# file10 register map
Vendor: Test Ltd.; Series: TestSeries; File version: 1.0
Test svd file for enumeratedValues derivedFrom
Registers are 32-bit, read-write, reset 0x0 unless marked. A register's access mark holds for its fields unless they carry their own. Offsets are from the block's base; lines under a group give offsets from that group; [hi:lo] are bit positions; {n}, {i} and the like mark numbered series; 'fields as' and 'values as' point back to an identical list; <NAME> marks a mode.

## Memory map
0x40000000 TestPeripheral

## TestPeripheral
Base 0x40000000
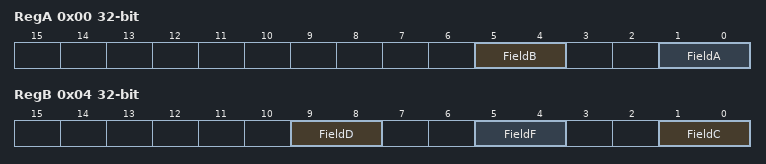
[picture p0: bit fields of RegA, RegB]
0x00 RegA — Register with the origin enumeratedValues sections
  [5:4] FieldB — Derives its enumeratedValues by a bare, unqualified name
    0=Disable device; 1=Enable device
  [1:0] FieldA — Origin field with a device-wide unique enumeratedValues name
    0=Disable device; 1=Enable device
0x04 RegB — Register whose fields reuse an enumeratedValues name that is not unique device-wide
  [9:8] FieldD — Derives its enumeratedValues qualified by the origin field name
    0=off (Off state); 1=on (On state)
  [5:4] FieldF — The other field sharing the same enumeratedValues name, to force disambiguation
    0=low (Low state); 1=High state
  [1:0] FieldC — One of two fields sharing the same enumeratedValues name
    0=off (Off state); 1=on (On state)

## Licence text in the file
MIT License
